# systim_secure register map
Vendor: Texas Instruments
Peripheral module from a debugger description file (folder CC35X1).
Registers are 32-bit, access per field, reset values left out (the file's numbers can be read two ways) unless marked. A register's access mark holds for its fields unless they carry their own. Offsets are as the file gives them; lines under a group give offsets from that group; [hi:lo] are bit positions; {n}, {i} and the like mark numbered series; 'fields as' and 'values as' point back to an identical list; <NAME> marks a mode.

## systim_secure
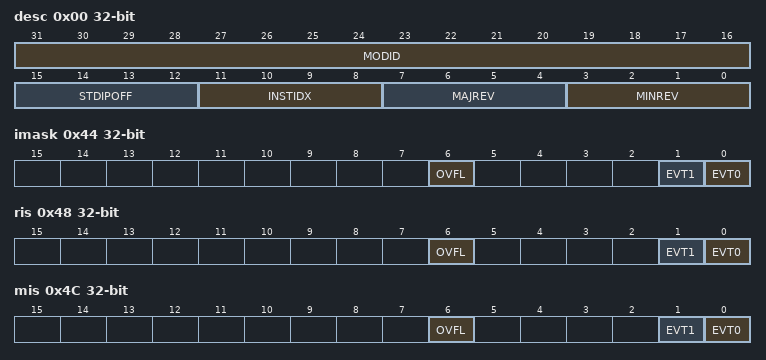
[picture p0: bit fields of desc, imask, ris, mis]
0x00 desc ro — This register identifies the peripheral and its exact version.
  [31:16] MODID — Module identifier MODID[15:0]. Used to uniquely identify this IP. See comment about derivation below
    0=MINIMUM (Smallest value); 0xFFFF=MAXIMUM (Highest possible value)
  [15:12] STDIPOFF — 64 B standard IP MMR block (beginning with aggregated IRQ registers) 0: STDIP MMRs do not exist 1:15: These MMRs begin at offset 64*STDIPOFF from IP base address
    0=MINIMUM (Smallest value); 15=MAXIMUM (Highest possible value)
  [11:8] INSTIDX — If multiple instances of IP exists in SOC, this field can identify the instance number 0-15
    values as STDIPOFF
  [7:4] MAJREV — Major revision of IP 0-15
    values as STDIPOFF
  [3:0] MINREV — Minor revision of IP 0-15.
    values as STDIPOFF
0x44 imask — INTERRUPT BIT MASK Interrupt Mask. If a bit is cleared, then corresponding interrupt is masked.
  [6] OVFL rw — Mask Timer Overflow Event in MIS register.
    0=CLR (Clear Interrupt Mask); 1=SET (Set Interrrupt Mask)
  [1] EVT1 rw — Mask EVENT1 in MIS register.
    0=CLR (Clear Interrupt Mask); 1=SET (Set Interrrupt Mask)
  [0] EVT0 rw — Mask EVENT0 in MIS register.
    0=CLR (Clear Interrupt Mask); 1=SET (Set Interrupt Mask)
0x48 ris ro — Raw interrupt status reflects all pending interrupts, regardless of masking. The RIS register allows the user to implement a poll scheme. A flag set in this register can be cleared by writing 1 to the ICLR register bit even if the corresponding IMASK bit is not enabled.
  [all] fields
    0=CLR (Interrupt did not occur); 1=SET (Interrupt occured)
  [6] OVFL — Raw interrupt status for Timer Overflow EVENT. This bit is set to 1 when an event is received on Timer Ovreflow EVENT channel.
  [1] EVT1 — Raw interrupt status for EVENT1. This bit is set to 1 when an event is received on EVENT1 channel.
  [0] EVT0 — Raw interrupt status for EVENT0. This bit is set to 1 when an event is received on EVENT0 channel.
0x4C mis ro — Masked interrupt status. This is an AND of the IMASK and RIS registers.
  [all] fields
    0=CLR (Interrupt did not occur); 1=SET (Interrupt occured)
  [6] OVFL — Mask Interrupt Status Timer Overflow Event in MIS register.
  [1] EVT1 — Mask interrupt status for EVENT1
  [0] EVT0 — Mask interrupt status for EVENT0
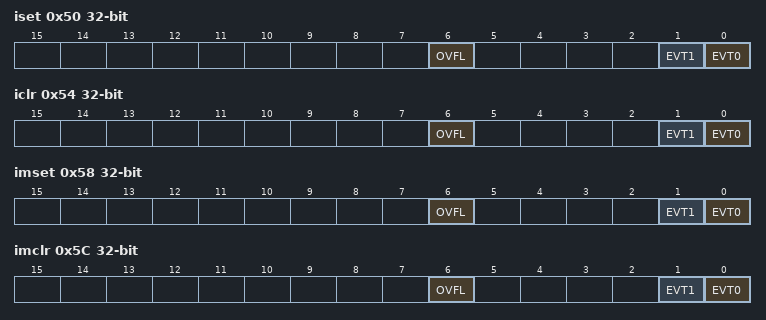
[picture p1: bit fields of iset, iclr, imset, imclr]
0x50 iset — Interrupt set. Allows interrupts to be set by software (useful in diagnostics and safety checks). Writing a 1 to a bit in ISET will set the event and therefore the related RIS bit also gets set. If the interrupt is enabled through the mask, then the corresponding MIS bit is also set.
  [all] fields
    0=NO_EFFECT (Writing 0 has no effect); 1=SET (Set Interrupt)
  [6] OVFL wo — Sets Timer Overflow EVENT in RIS
  [1] EVT1 wo — Sets channel1 EVENT in RIS
  [0] EVT0 wo — Sets channel0 EVENT in RIS
0x54 iclr — Interrupt clear. Write a 1 to clear corresponding Interrupt.
  [all] fields
    0=NO_EFFECT (Writing 0 has no effect); 1=CLR (Clear Interrupt)
  [6] OVFL wo — Overflow
  [1] EVT1 wo — Clears EVENT1 in RIS
  [0] EVT0 wo — Clears EVENT0 in RIS
0x58 imset — Interrupt mask set. Writing a 1 to a bit in IMSET will set the related IMASK bit.
  [all] fields
    0=NO_EFFECT (Writing 0 has no effect); 1=SET (Set interrupt mask)
  [6] OVFL wo — Sets Timer Overflow Event.
  [1] EVT1 wo — Sets channel1 Event
  [0] EVT0 wo — Sets channel0 Event
0x5C imclr — Interrupt mask clear. Writing a 1 to a bit in IMCLR will clear the related IMASK bit.
  [all] fields
    0=NO_EFFECT (Writing 0 has no effect); 1=CLR (Clear interrupt mask)
  [6] OVFL wo — Clears Timer Overflow Event.
  [1] EVT1 wo — Clears channel1 Event.
  [0] EVT0 wo — Clears channel0 Event.
0x60 emu — This register can be used by the software developer to control the behavior of the peripheral relative to the CPU Halted input.
  [0] HALT rw — This bit controls peripheral behavior at CPU halt condition.
    0=RUN (Peripheral ignores the state of the CPU Halted input); 1=STOP (Peripheral freezes functionality immediately or at appropriate time when the CPU Halted input is asserted and resumes when it is deasserted)
0x64 dtb — Digital Test Bus. This register is used to bring out some internal signals of the peripheral on digital test bus (DTB).
  [3:0] SEL rw — This bit field is used to select DTB mux digital output signals.
    0=DISABLE (DTB output from peripheral is 0x0.); {v}=GRP{v} (Selects test group {v}) (v=1..7); {v}=GRP{v} (Selects test group 7) (v=8..15)
0x100 cnt0 ro — Systimer Counter Value[31:0]. Time with 250ns resolution from systimer
  [31:0] VAL — Counter Value. This is not writable while the systimer counter is enabled
    0=MINIMUM (Smallest value); 0xFFFFFFFF=MAXIMUM (Highest possible value)
0x104 cnt1 ro — Systimer Counter Value[33:2]. Time with 1us resolution from systimer
  fields as cnt0
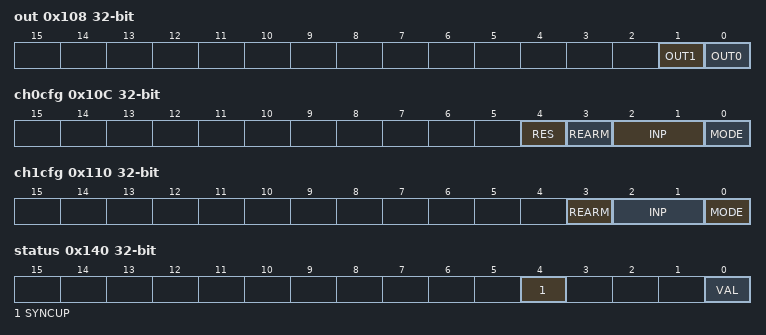
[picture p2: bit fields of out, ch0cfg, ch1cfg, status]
0x108 out ro — SYSTIMER'S Channel Output Event Values
  [1] OUT1 — Output Value of channel 1.
    0=CLR (Event did not occur.); 1=SET (Event occured)
  [0] OUT0 — Output Value of channel 0.
    0=CLR (Event did not occur.); 1=SET (Event occured)
0x10C ch0cfg — SYSTIMER channel 0 configuration
  [4] RES rw — This bit decides the RESOLUTION of the channel that will be used.
    0=US (Channel Works in Timer's 1us Resolution.); 1=NS (Channel Works in Timer's 250ns resolution)
  [3] REARM rw — When Rearm is enabled the channel remains in continuous capture mode. Otherwise it'll be in One shot capture mode. Rearm is only valid for capture mode.
    1=EN (Re arm is enabled); 0=NS (Re Arm is disabled)
  [2:1] INP rw — Decides the channel input signal's mode. Setting the Value as 2'b11 selects the Rise Function.
    0=RISE (Capture on rising edge); 1=FALL (Capture on Falling Edge); 2=BOTH (Capture on both Edge)
  [0] MODE rw — Decides the channel mode.
    0=DIS (Channel is disabled); 1=CAPT (Channel is in capture mode)
0x110 ch1cfg — SYSTIMER channel 1 configuration
  [3] REARM rw — When Rearm is enabled the channel remains in continous capture mode. Otherwise it'll be in One shot capture mode. Rearm is only valid for capture mode.
    1=EN (Re arm is enabled); 0=NS (Re Arm is disabled)
  [2:1] INP rw — Decides the channel input signal's mode. Setting the Value as 2'b11 selects the Rise Function
    values as ch0cfg.INP
  [0] MODE rw — Decides the channel mode.
    values as ch0cfg.MODE
0x120 ch0val rw — System Timer Channel 0 Capture/Compare Register. This Register when written with any compare value will arm the channel to work in compare mode.
  [31:0] VAL — Capture/compare value
    values as cnt0.VAL
0x124 ch1val rw — System Timer Channel 1 Capture/Compare Register. This Register when written with any compare value will arm the channel to work in compare mode.
  fields as ch0val
0x134 timebit — This Register will be used to specify which TIME bit is required by LGPT to be forwarded from SYSTIMER.
  [15:0] VAL rw — The corresponding bit will have value '1' rest should be '0'. If more than one bit is asserted, output is "or" of all the bits.
    0=NOBIT (No bit is forwarded to the event fabric.); 2=BIT3 (Bit3 is forwarded to the event fabric.); 4=BIT4 (Bit4 is forwarded to the event fabric.); 8=BIT5 (Bit5 is forwarded to the event fabric.); 16=BIT6 (Bit6 is forwarded to the event fabric.); 32=BIT7 (Bit7 is forwarded to the event fabric.); 64=BIT8 (Bit8 is forwarded to the event fabric.); 128=BIT9 (Bit9 is forwarded to the event fabric.); 0x100=BIT10 (Bit10 is forwarded to the event fabric.); 0x200=BIT11 (Bit11 is forwarded to the event fabric.); 0x400=BIT12 (Bit12 is forwarded to the event fabric.); 0x800=BIT13 (Bit13 is forwarded to the event fabric.); 0x1000=BIT14 (Bit14 is forwarded to the event fabric.); 0x2000=BIT15 (Bit15 is forwarded to the event fabric.); 0x4000=BIT16 (Bit16 is forwarded to the event fabric.); 0x8000=BIT17 (Bit17 is forwarded to the event fabric.); 1=BIT2 (Bit2 is forwarded to the event fabric.)
0x138 kp — PI filter's Proportional Gain Value
  [3:0] VAL rw — Proportional Error is left shifted by this value.
    values as desc.STDIPOFF
0x13C ki — PI filter's Accumulator's Gain Value
  [3:0] VAL rw — Accumulated Error is left shifted by this value.
    values as desc.STDIPOFF
0x140 status ro — STATUS This is the system timer status register.
  [4] SYNCUP — This bit indicates the status of resyncup of systimer with RTC. The bitfield has a reset value of '1' , as out of reset the systimer syncs up with RTC, after the first_synced_lftick occurs the SYNCUP bit goes to zero.
    0=CLR (SYNC UP with RTC is not happening); 1=SET (Any write to STATUS register, triggers the SYNCUP with RTC and this bit is set.)
  [0] VAL — This bit indicates if the system time is initialized and running.
    0=STOP (system timer is not running.); 1=RUN (system timer is running)
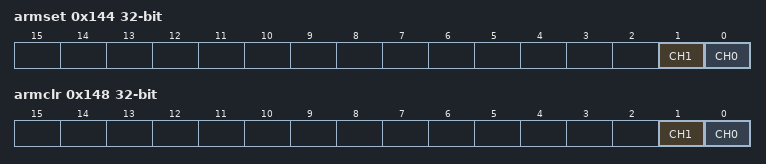
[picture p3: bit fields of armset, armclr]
0x144 armset — ARMSET on read gives out the status of the 2 channels 1. Channel state UNARMED returns 0 2. Channel state CAPTURE or COMPARE returns 1 A write to ARMSET has for each channel the following effect: 1. If ARMSTA[x]==0 -> no effect 2. If ARMSTA[x]==1 and channel x is in CAPTURE state then no effect on the channel 3. Else Set channel in COMPARE mode using existing CHxVAL value
  [1] CH1 rw — Arming Channel 1 for either compare or capture operation.
    0=NOEFFECT (No effect on the channel); 1=SET (if channel 1 is in CAPTURE state then no effect on the channel Else ; Set channel in COMPARE mode using existing CH1VAL value)
  [0] CH0 rw — Arming Channel 0 for either compare or capture operation.
    0=NOEFFECT (No effect on the channel); 1=SET (if channel 0 is in CAPTURE state then no effect on the channel 3. Else ; Set channel in COMPARE mode using existing CH0VAL value)
0x148 armclr — ARMCLR on read gives out the status of the 2 channels 1. Channel state UNARMED returns 0 2. Channel state CAPTURE or COMPARE returns 1 A write to ARMCLR has for each channel the following effect: 1. If ARMCLR[x]==0 no effect 2. Else Set channel in UNARMED state without triggering event unless a compare/capture event happens in the same cycle
  [1] CH1 rw — Disarming Channel 1
    0=NOEFFECT (No effect on the channel); 1=CLR (Set channel in UNARMED state without triggering event unless a compare/capture event happens in the same cycle)
  [0] CH0 rw — Disarming Channel 0
    values as CH1
0x14C ch0sr rw — Save/restore alias registers Channel 0. i. A read to CH0SR behaves exactly as a read to CH0VAL. A write to CH0SR sets CH0VAL value of register without affecting channel state or configuration
  fields as ch0val
0x150 ch1sr rw — Save/restore alias registers Channel 1. i. A read to CH1SR behaves exactly as a read to CH1VAL. A write to CH1SR sets CH1VAL value of register without affecting channel state or configuration.
  fields as ch0val
0x1000 clk_en — CLOCK CONFIG
  [0] EN rw — ENABLE '1' - enable systimer clk '0' - disable systimer clk
